# NUC400_v1 register map
File version: 1.0
Registers are 32-bit, read-write, reset 0x0 unless marked. A register's access mark holds for its fields unless they carry their own. Offsets are from the block's base; [hi:lo] are bit positions; 'fields as' and 'values as' point back to an identical list.

## UART0 — UART Register Map
Base 0x40070000
0x00 UART_DAT reset not defined — UARTx Receive / Transmit Buffer Register
  [7:0] DAT — Receiving/Transmit Buffer. Write Operation: By writing one byte to this register, the data byte will be stored in transmitter FIFO. The. UART Controller will send out the data stored in transmitter FIFO top location through the. UART_TXD. Read Operation: By reading this register, the UART will return an 8-bit data received from receiving FIFO
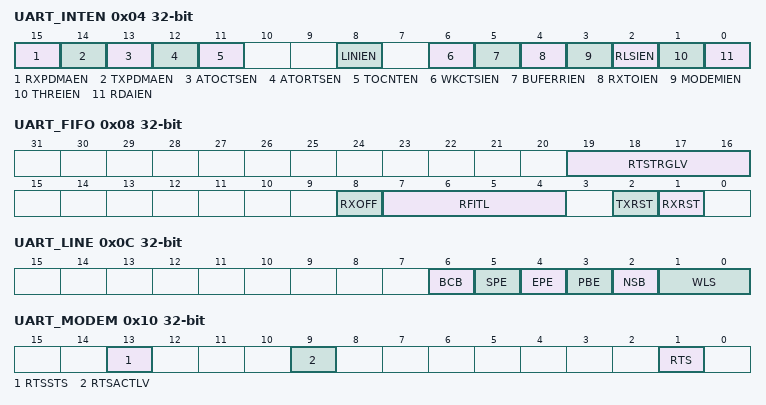
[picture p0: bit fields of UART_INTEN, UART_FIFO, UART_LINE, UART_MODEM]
0x04 UART_INTEN — UARTx Interrupt Enable Register
  [15] RXPDMAEN — RX DMA Enable Bit. This bit can enable or disable RX DMA service.
    0=RX DMA Disabled; 1=RX DMA Enabled
  [14] TXPDMAEN — TX DMA Enable Bit. This bit can enable or disable TX DMA service.
    0=TX DMA Disabled; 1=TX DMA Enabled
  [13] ATOCTSEN — CTS Auto Flow Control Enable Bit. When CTS auto-flow is enabled, the UART will send data to external device when CTS input assert (UART will not send data to device until CTS is asserted).
    0=CTS auto flow control Disabled; 1=CTS auto flow control Enabled
  [12] ATORTSEN — RTS Auto Flow Control Enable Bit. When RTS auto-flow is enabled, if the number of bytes in the RX FIFO equals the RTSTRGLV (UART_FIFO[19:16]), the UART will de-assert RTS signal.
    0=RTS auto flow control Disabled; 1=RTS auto flow control Enabled
  [11] TOCNTEN — Time-Out Counter Enable Bit
    0=Time-out counter Disabled; 1=Time-out counter Enabled
  [8] LINIEN — LIN RX Break Field Detected Interrupt Enable Bit. Note: This field is used for LIN function mode.
    0=Lin bus RX break filed interrupt Disabled; 1=Lin bus RX break filed interrupt Enabled
  [6] WKCTSIEN — UART Wake-Up Function Enable Bit
    0=UART wake-up function Disabled; 1=UART wake-up function Enabled when the chip is in Power-down mode, an external CTS change will wake up chip from Power-down mode
  [5] BUFERRIEN — Buffer Error Interrupt Enable Bit
    0=INT_BUF_ERR Disabled; 1=INT_BUF_ERR Enabled
  [4] RXTOIEN — RX Time-Out Interrupt Enable Bit
    0=NT_TOUT Disabled; 1=INT_TOUT Enabled
  [3] MODEMIEN — Modem Status Interrupt Enable Bit
    0=INT_MODEM Disabled; 1=INT_MODEM Enabled
  [2] RLSIEN — Receive Line Status Interrupt Enable Bit
    0=INT_RLS Disabled; 1=INT_RLS Enabled
  [1] THREIEN — Transmit Holding Register Empty Interrupt Enable Bit
    0=INT_THRE Disabled; 1=INT_THRE Enabled
  [0] RDAIEN — Receive Data Available Interrupt Enable Bit
    0=INT_RDA Disabled; 1=INT_RDA Enabled
0x08 UART_FIFO — UARTx FIFO Control Register
  [19:16] RTSTRGLV — RTS Trigger Level For Auto-Flow Control Use
  [8] RXOFF — Receiver Disable. The receiver is disabled or not. Note: This field is used for RS-485 Normal Multi-drop mode. It should be programmed before RS-485_NMM (UART_ALTCTL [8]) is programmed.
    0=Receiver Enabled; 1=Receiver Disabled
  [7:4] RFITL — RX FIFO Interrupt (INT_RDA) Trigger Level
  [2] TXRST — TX Field Software Reset. When TX_RST is set, all the byte in the transmit FIFO and TX internal state machine are cleared. Note: This bit will auto clear needs at least 3 UART engine clock cycles.
    0=No effect; 1=Reset the TX internal state machine and pointers
  [1] RXRST — RX Field Software Reset. When RX_RST is set, all the byte in the receiver FIFO and RX internal state machine are cleared. Note: This bit will be automatically cleared for at least 3 UART engine clock cycles.
    0=No effect; 1=Reset the RX internal state machine and pointers
0x0C UART_LINE — UARTx Line Control Register
  [6] BCB — Break Control. When this bit is set to logic 1, the serial data output (TX) is forced to the Spacing State (logic 0). This bit acts only on TX and has no effect on the transmitter logic.
  [5] SPE — Stick Parity Enable Bit
    0=Stick parity Disabled; 1=If bit 3 and 4 are logic 1, the parity bit is transmitted and checked as logic 0. If bit 3 is 1 and bit 4 is 0 then the parity bit is transmitted and checked as 1
  [4] EPE — Even Parity Enable Bit. This bit is effective only when bit 3 (parity bit enable) is set.
    0=Odd number of logic 1's is transmitted and checked in each word; 1=Even number of logic 1's is transmitted and checked in each word
  [3] PBE — Parity Bit Enable Bit
    0=No parity bit; 1=Parity bit is generated on each outgoing character and is checked on each incoming data
  [2] NSB — Number Of "STOP Bit" Two "STOP bit" is generated when 6-, 7- and 8-bit word length is selected.
    0=One " STOP bit" is generated in the transmitted data; 1=One and a half " STOP bit" is generated in the transmitted data when 5-bit word length is selected
  [1:0] WLS — Word Length Selection
0x10 UART_MODEM — UARTx Modem Control Register
  [13] RTSSTS ro — RTS Pin State (Read Only). This bit is the output pin status of RTS.
  [9] RTSACTLV — RTS Trigger Level. This bit can change the RTS trigger level.
    0=Low level triggered; 1=High level triggered
  [1] RTS — RTS (Request-To-Send) Signal
    0=Drive RTS pin to logic 1 (If the RTSACTLV set to low level triggered). Drive RTS pin to logic 0 (If the RTSACTLV set to high level triggered); 1=Drive RTS pin to logic 0 (If the RTSACTLV set to low level triggered). Drive RTS pin to logic 1 (If the RTSACTLV set to high level triggered)
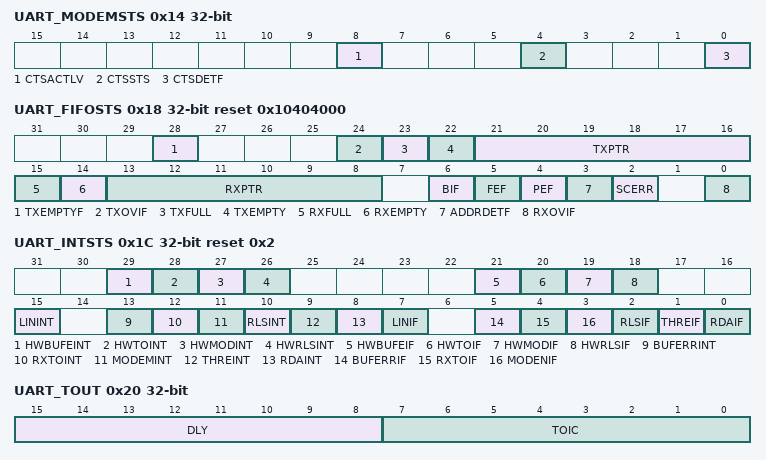
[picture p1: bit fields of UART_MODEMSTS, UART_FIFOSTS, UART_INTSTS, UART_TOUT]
0x14 UART_MODEMSTS — UARTx Modem Status Register
  [8] CTSACTLV — CTS Trigger Level. This bit can change the CTS trigger level.
    0=Low level triggered; 1=High level triggered
  [4] CTSSTS ro — CTS Pin Status (Read Only). This bit is the pin status of CTS.
  [0] CTSDETF ro — Detect CTS State Change Flag (Read Only). This bit is set whenever CTS input has change state, and it will generate Modem interrupt to CPU when MODEMIEN (UART_INTEN[3]) is set to 1. Software can write 1 to clear this bit to 0
0x18 UART_FIFOSTS reset 0x10404000 — UARTx FIFO Status Register
  [28] TXEMPTYF ro — Transmitter Empty Flag (Read Only). Bit is set by hardware when TX FIFO (UART_DAT) is empty and the STOP bit of the last byte has been transmitted. Bit is cleared automatically when TX FIFO is not empty or the last byte transmission has not completed.
  [24] TXOVIF ro — TX Overflow Error Interrupt Flag (Read Only). If TX FIFO (UART_DAT) is full, an additional write to UART_DAT will cause this bit to logic 1. Note: This bit is read only, but it can be cleared by writing '1' to it.
  [23] TXFULL ro — Transmitter FIFO Full (Read Only). This bit indicates TX FIFO full or not. This bit is set when TXPTR is equal to 64/16(UART0/UART1~5), otherwise is cleared by hardware.
  [22] TXEMPTY ro — Transmitter FIFO Empty (Read Only). This bit indicates TX FIFO empty or not. When the last byte of TX FIFO has been transferred to Transmitter Shift Register, hardware sets this bit high. It will be cleared when writing data into DAT (TX FIFO not empty).
  [21:16] TXPTR ro — TX FIFO Pointer (Read Only). This field indicates the TX FIFO Buffer Pointer. When CPU writes one byte into UART_DAT, TXPTR increases one. When one byte of TX FIFO is transferred to Transmitter Shift Register, TXPTR decreases one.
  [15] RXFULL ro — Receiver FIFO Full (Read Only). This bit initiates RX FIFO full or not. This bit is set when RXPTR is equal to 64/16(UART0/UART1~5), otherwise is cleared by hardware.
  [14] RXEMPTY ro — Receiver FIFO Empty (Read Only). This bit initiate RX FIFO empty or not. When the last byte of RX FIFO has been read by CPU, hardware sets this bit high. It will be cleared when UART receives any new data.
  [13:8] RXPTR ro — RX FIFO Pointer (Read Only). This field indicates the RX FIFO Buffer Pointer. When UART receives one byte from external device, RXPTR increases one. When one byte of RX FIFO is read by CPU, RXPTR decreases one.
  [6] BIF ro — Break Interrupt Flag (Read Only). This bit is set to a logic 1 whenever the received data input(RX) is held in the "spacing state" (logic 0) for longer than a full word transmission time (that is, the total time of "start bit" + data bits + parity + stop bits) and is reset whenever the CPU writes 1 to this bit. Note: This bit is read only, but it can be cleared by writing '1' to it.
  [5] FEF ro — Framing Error Flag (Read Only). This bit is set to logic 1 whenever the received character does not have a valid "stop bit" (that is, the stop bit following the last data bit or parity bit is detected as a logic 0), and is reset whenever the CPU writes 1 to this bit. Note: This bit is read only, but it can be cleared by writing '1' to it.
  [4] PEF ro — Parity Error Flag (Read Only). This bit is set to logic 1 whenever the received character does not have a valid "parity bit", and is reset whenever the CPU writes 1 to this bit. Note: This bit is read only, but it can be cleared by writing '1' to it.
  [3] ADDRDETF ro — RS-485 Address Byte Detection Flag (Read Only). Note1: This field is used for RS-485 function mode. Note2: This bit is read only, but it can be cleared by writing '1' to it.
  [2] SCERR — Smart Card Over Error Retry Flag. It is set to 1 when transmitter re-transmits over the retry number (TXRTY (UART_SCCTL[6:4])) or the receiver transfer error retry over retry number (RXRTY (UART_SCCTL[2:0])). Note1: This field is used for SC function mode. Note2: This bit is read only, but it can be cleared by writing '1' to it.
    0=No any transmitter re-transmits over or receiver transfer error retry over; 1=one of the transmitter re-transmits over active or receiver transfer error retry over active
  [0] RXOVIF ro — RX Overflow Error IF (Read Only). This bit is set when RX FIFO overflow. If the number of bytes of received data is greater than RX_FIFO (UART_DAT) size, 64/16 bytes of UART0/UART1, this bit will be set. Note: This bit is read only, but it can be cleared by writing '1' to it.
0x1C UART_INTSTS reset 0x2 — UARTx Interrupt Status Register
  [29] HWBUFEINT ro — In DMA Mode, Buffer Error Interrupt Indicator (Read Only). This bit is set if BUFERRIEN and HWBFERIF are both set to 1.
    0=No buffer error interrupt is generated in DMA mode; 1=The buffer error interrupt is generated in DMA mode
  [28] HWTOINT ro — In DMA Mode, Time-Out Interrupt Indicator (Read Only). This bit is set if RXTOIEN and HWTOIF are both set to 1.
    0=No Tout interrupt is generated in DMA mode; 1=Tout interrupt is generated in DMA mode
  [27] HWMODINT ro — In DMA Mode, MODEM Status Interrupt Indicator (Read Only). This bit is set if MODEMIEN and HWMODIF are both set to 1.
    0=No Modem interrupt is generated in DMA mode; 1=Modem interrupt is generated in DMA mode
  [26] HWRLSINT ro — In DMA Mode, Receive Line Status Interrupt Indicator (Read Only). This bit is set if RLSIEN and HWRLSIF are both set to 1.
    0=No RLS interrupt is generated in DMA mode; 1=RLS interrupt is generated in DMA mode
  [21] HWBUFEIF ro — In DMA Mode, Buffer Error Interrupt Flag (Read Only). This bit is set when the TX or RX FIFO overflows (TXOVIF or RXOVIF is set). When BERRIF is set, the transfer maybe is not correct. If BUFERRIEN bit (UART_INTEN [5]) is enabled, the buffer error interrupt will be generated. Note: This bit is cleared when both TXOVIF and RXOVIF are cleared.
  [20] HWTOIF ro — In DMA Mode, Time-Out Interrupt Flag (Read Only). This bit is set when the RX FIFO is not empty and no activities occurred in the RX FIFO and the time-out counter equal to TOIC. If TOCNTEN (UART_INTEN[11]) is enabled, the Time-out interrupt will be generated. Note: This bit is read only and user can read UART_DAT (RX is in active) to clear it.
  [19] HWMODIF ro — In DMA Mode, MODEM Interrupt Flag (Read Only). Note: This bit is read only and reset to 0 when bit CTSDETF is cleared by a write 1 on CTSDETF.
  [18] HWRLSIF ro — In DMA Mode, Receive Line Status Flag (Read Only). This bit is set when the RX receive data have parity error, framing error or break error (at least one of 3 bits, BIF, FEF and PEF, is set). If RLSIEN bit (UART_INTEN[2]) is enabled, the RLS interrupt will be generated. Note2: In SC function mode, this field includes "error retry over flag . Note3: This bit is read only and reset to 0 when all bits of BIF, FEF and PEF are cleared.
  [15] LININT ro — LIN Bus Interrupt Indicator (Read Only). This bit is set if LINIEN and LINIF are both set to 1.
    0=No LIN RX Break interrupt is generated; 1=LIN RX Break interrupt is generated
  [13] BUFERRINT ro — Buffer Error Interrupt Indicator (Read Only). This bit is set if BUFERRIEN and BERRIF are both set to 1.
    0=No buffer error interrupt is generated; 1=The buffer error interrupt is generated
  [12] RXTOINT ro — Time-Out Interrupt Indicator (Read Only). This bit is set if TOCNTEN and RXTOIF are both set to 1.
    0=No Tout interrupt is generated; 1=Tout interrupt is generated
  [11] MODEMINT ro — MODEM Status Interrupt Indicator (Read Only). This bit is set if MODEMIEN and MODENIF are both set to 1.
    0=No Modem interrupt is generated; 1=Modem interrupt is generated
  [10] RLSINT ro — Receive Line Status Interrupt Indicator (Read Only). This bit is set if RLSIEN and RLSIF are both set to 1.
    0=No RLS interrupt is generated; 1=RLS interrupt is generated
  [9] THREINT ro — Transmit Holding Register Empty Interrupt Indicator (Read Only). This bit is set if THREIEN and THREIF are both set to 1.
    0=No THRE interrupt is generated; 1=THRE interrupt is generated
  [8] RDAINT ro — Receive Data Available Interrupt Indicator (Read Only). This bit is set if RDAIEN and RDAIF are both set to 1.
    0=No RDA interrupt is generated; 1=RDA interrupt is generated
  [7] LINIF ro — LIN Bus Flag (Read Only). Note: This bit is cleared when both SLVHDETF and LIN_BRDER_F and BITEF and LINS_IDPENR_F and SLVHEF are cleared
  [5] BUFERRIF ro — Buffer Error Interrupt Flag (Read Only). This bit is set when the TX or RX FIFO overflows (TXOVIF or RXOVIF is set). When BERRIF is set, the transfer maybe is not correct. If BUFERRIEN bit (UART_INTEN[5]) is enabled, the buffer error interrupt will be generated. Note: This bit is cleared when both TXOVIF and RXOVIF are cleared.
  [4] RXTOIF ro — Time-Out Interrupt Flag (Read Only). This bit is set when the RX FIFO is not empty and no activities occurred in the RX FIFO and the time-out counter equal to TOIC. If TOCNTEN bit (UART_INTEN[11]) is enabled, the Time-out interrupt will be generated. Note: This bit is read only and user can read UART_DAT (RX is in active) to clear it.
  [3] MODENIF ro — MODEM Interrupt Flag (Read Only). Note: This bit is read only and reset to 0 when bit CTSDETF is cleared by a write 1 on CTSDETF.
  [2] RLSIF ro — Receive Line Interrupt Flag (Read Only). This bit is set when the RX receive data have parity error, framing error or break error (at least one of 3 bits, BIF, FEF and PEF, is set). If RLSIEN bit (UART_INTEN[2]) is enabled, the RLS interrupt will be generated. Note2: In SC function mode, this field includes "error retry over flag . Note3: This bit is read only and reset to 0 when all bits of BIF, FEF and PEF are cleared.
  [1] THREIF ro — Transmit Holding Register Empty Interrupt Flag (Read Only). This bit is set when the last data of TX FIFO is transferred to Transmitter Shift Register. If THREIEN bit (UART_INTEN[1]) is enabled, the THRE interrupt will be generated. Note: This bit is read only and it will be cleared when writing data into DAT (TX FIFO not empty).
  [0] RDAIF ro — Receive Data Available Interrupt Flag (Read Only). When the number of bytes in the RX FIFO equals the RFITL then the RDAIF will be set. If RDAIEN bit (UART_INTEN[0]) is enabled, the RDA interrupt will be generated. Note: This bit is read only and it will be cleared when the number of unread bytes of RX FIFO drops below the threshold level (RFITL).
0x20 UART_TOUT — UARTx Time-out Register
  [15:8] DLY — TX Delay Time Value. This field is use to programming the transfer delay time between the last stop bit and next start bit. . Note: The counter clock is baud rate clock
  [7:0] TOIC — Time-Out Interrupt Comparator
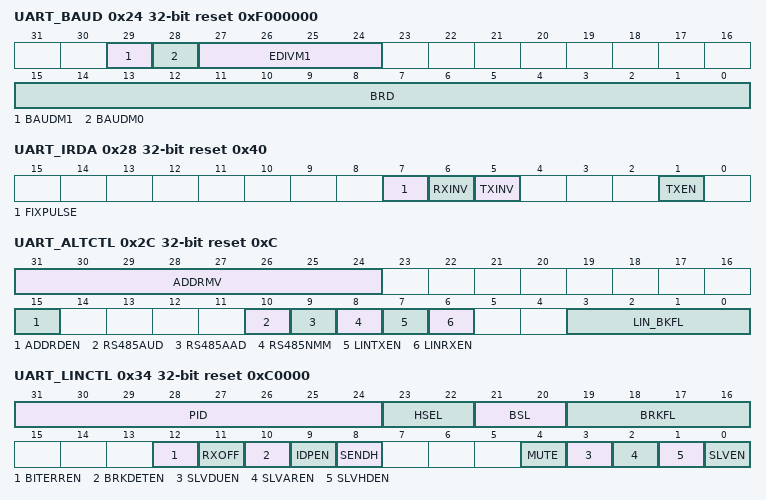
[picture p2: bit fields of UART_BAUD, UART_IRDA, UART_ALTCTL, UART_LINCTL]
0x24 UART_BAUD reset 0xF000000 — UARTx Baud Rate Divisor Register
  [29] BAUDM1 — Divider X Enable Bit. Refer to the table below for more information. Note: In IrDA mode, this bit must disable.
    0=Divider X Disabled (the equation of M = 16); 1=Divider X Enabled (the equation of M = X+1, but EDIVM1 (UART_BAUD[27:24]) must = 8)
  [28] BAUDM0 — Divider X Equal To 1. Refer to the table below for more information.
    0=Divider M = X (the equation of M = X+1, but EDIVM1 (UART_BAUD[27:24]) must = 8); 1=Divider M = 1 (the equation of M = 1, but BRD (UART_BAUD[15:0]) must = 3)
  [27:24] EDIVM1 — Divider X
  [15:0] BRD — Baud Rate Divider. The field indicated the baud rate divider
0x28 UART_IRDA reset 0x40 — UARTx IrDA Control Register
  [7] FIXPULSE — Pulse width of TX is fixed 1.6us.
  [6] RXINV — IrDA Inverse Receive Input Signal
    0=None inverse receiving input signal; 1=Inverse receiving input signal. (Default)
  [5] TXINV — IrDA Inverse Transmitting Output Signal
    0=None inverse transmitting signal. (Default); 1=Inverse transmitting output signal
  [1] TXEN — IrDA Receiver/Transmitter Selection Enable Bit
    0=IrDA Transmitter Disabled and Receiver Enabled. (Default); 1=IrDA Transmitter Enabled and Receiver Disabled
0x2C UART_ALTCTL reset 0xC — UARTx Alternate Control/Status Register
  [31:24] ADDRMV — Address Match Value. This field contains the RS-485 address match values. Note: This field is used for RS-485 auto address detection mode.
  [15] ADDRDEN — RS-485 Address Detection Enable Bit. This bit is use to enable RS-485 address detection mode. Note: This field is used for RS-485 any operation mode.
    0=address detection mode Disabled; 1=Address detection mode Enabled
  [10] RS485AUD — RS-485 Auto Direction Mode (AUD). Note: It can be active with RS-485_AAD or RS-485_NMM operation mode.
    0=RS-485 Auto Direction Operation (AUO) mode Disabled; 1=RS-485 Auto Direction Operation (AUO) mode Enabled
  [9] RS485AAD — RS-485 Auto Address Detection Operation Mode (AAD). Note: It can't be active with RS-485_NMM operation mode.
    0=RS-485 Auto Address Detection (AAD) Operation mode Disabled; 1=RS-485 Auto Address Detection (AAD) Operation mode Enabled
  [8] RS485NMM — RS-485 Normal Multi-Drop Operation Mode (NMM). Note: It can't be active with RS-485_AAD operation mode.
    0=RS-485 Normal Multi-drop Operation Mode (NMM) Disabled; 1=RS-485 Normal Multi-drop Operation Mode (NMM) Enabled
  [7] LINTXEN — LIN TX Break Mode Enable Bit. The LIN TX header can be "break field" or "break and sync field" or "break, sync and frame ID field" depending on the setting HSEL register. Note: When transmitter header field (it may be "break" or "break + sync" or "break + sync + frame ID" selected by HSEL field) transfer operation finished, this bit will be cleared automatically.
    0=Send LIN TX header Disabled; 1=Send LIN TX header Enabled
  [6] LINRXEN — LIN RX Enable Bit
    0=LIN RX mode Disabled; 1=LIN RX mode Enabled
  [3:0] LIN_BKFL — LIN Break Field Length. This field indicates a 4-bit LIN TX break field count. Note1: This break field length is BRKFL + 1.
0x30 UART_FUNCSEL — UARTx Function Select Register
  [2:0] FUNCSEL — Function Select Enable Bit
    0=UART function; 1=LIN function Enabled; 2=IrDA function Enabled; 3=RS-485 function Enabled; 4=Smart-Card function Enabled
0x34 UART_LINCTL reset 0xC0000 — UARTx LIN Control Register
  [31:24] PID — This Field Contains The LIN Frame ID Value In LIN Function Mode, The Frame ID Parity Can Be Generated By Software Or Hardware Depending On UART_LINCTL [IDPEN] . Note1: User can fill any 8-bit value to this field and the bit 24 indicates ID0 (LSB first). Note2: This field can be used for LIN Master mode or Slave mode.
  [23:22] HSEL — LIN Header Selection
    0=LIN header includes "break field"; 1=LIN header includes "break field" and "sync field"; 2=LIN header includes "break field", "sync field" and "frame ID field"; 3=LIN header includes "break field", "sync field" and "frame ID field", but this mode only supports Receiver mode, not support transmitter mode. This mode difference with mode "10"; in this mode, the receiver will receive ID field (not check the PID (UART_LINCTL[31:24]) register) and when received ID field the SLVHDETF will be asserted (if SLVHDEN (UART_LINCTL[1]) be set)
  [21:20] BSL — LIN Break/Sync Delimiter Length . Note: This bit used for LIN master to send header field.
    0=LIN break/sync delimiter length is 1 bit time; 2=The LIN break/sync delimiter length is 2 bit time. The LIN break/sync delimiter length is 3 bit time; 3=The LIN break/sync delimiter length is 4 bit time
  [19:16] BRKFL — LIN Break Field Length. This field indicates a 4-bit LIN TX break field count. Note1: These registers are shadow registers of LIN_BKFL (UART_ALTCTL[3:0]), User can read/write it by setting LIN_BKFL (UART_ALTCTL[3:0]) or LIN_BKFL (UART_LINCTL[19:16]). Note2: This break field length is BRKFL + 1.
  [12] BITERREN — Bit Error Detect Enable Bit. Note: In LIN function mode, when occur bit error, hardware will generate an interrupt to CPU (INT_LIN) and the BITEF (UART_LINSTS[9]) flag will be asserted.
    0=Bit error detection function Disabled; 1=Bit error detection Enabled
  [11] RXOFF
    values as BITERREN
  [10] BRKDETEN — LIN Break Detection Enable Bit
    0=LIN break detection Disabled; 1=LIN break detection Enabled
  [9] IDPEN — LIN ID Parity Enable Bit
    0=LIN frame ID parity Disabled; 1=LIN frame ID parity Enabled
  [8] SENDH — LIN TX Send Header Enable Bit. The LIN TX header can be "break field" or "break and sync field" or "break, sync and frame ID field" depending on the setting HSEL register. Note: When transmitter header field (it may be "break" or "break + sync" or "break + sync + frame ID" selected by HSEL field) transfer operation finished, this bit will be cleared automatically.
    0=Send LIN TX header Disabled; 1=Send LIN TX header Enabled
  [4] MUTE — LIN Mute Mode Enable Bit. Note: The wake-up condition from mute mode and each control and interactions of this field are explained in 6.16.5.3.
    0=LIN mute mode. Disabled; 1=LIN mute mode Enabled
  [3] SLVDUEN — LIN Slave Divider Update Method Enable Bit. Note2: This bit is used for LIN slave automatic resynchronization mode (for non-automatic resynchronization mode, this bit should be kept cleared). Note3: The control and interactions of this field are explained in 6.16.5.3.
    0=UART_BAUD is updated as soon as UART_BAUD is writing by software (if no automatic resynchronization update occurs at the same time); 1=UART_BAUD is updated at the next received character. User must set the bit before checksum reception
  [2] SLVAREN — LIN Slave Automatic Resynchronization Mode Enable Bit. Note2: When operating in Automatic Resynchronization mode, the baud rate setting must be mode2 (BAUDM1 (UART_BAUD[29]) and BAUDM0 (UART_BAUD[28]) must be 1). Note3: The control and interactions of this field are explained in 6.16.5.3.
    0=LIN automatic resynchronization Disabled; 1=LIN automatic resynchronization Enabled
  [1] SLVHDEN — LIN Slave Header Detection Enable Bit. Note2: In LIN function mode, when header field (break + sync + frame ID) is detected, hardware will generate an interrupt to CPU (INT_LIN) and the SLVHDETF flag (UART_LINSTS[0]) will be asserted.
    0=LIN slave header detection Disabled; 1=LIN slave header detection Enabled
  [0] SLVEN — LIN Slave Mode Enable Bit
    0=LIN slave mode Disabled; 1=LIN slave mode Enabled
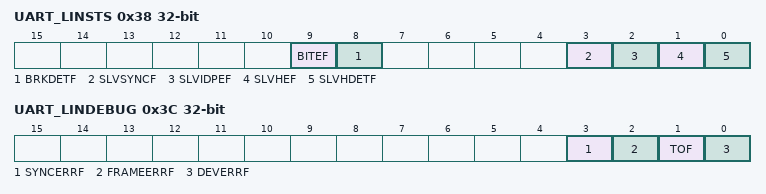
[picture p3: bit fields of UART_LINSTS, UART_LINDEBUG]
0x38 UART_LINSTS — UARTx LIN Status Register
  [9] BITEF ro — Bit Error Detect Status Flag (Read Only). At TX transfer state, hardware will monitoring the bus state, if the input pin (SIN) state not equals to the output pin (SOUT) state, BITEF will be set. When occur bit error, hardware will generate an interrupt to CPU (INT_LIN). Note1: This bit is read only, but can be cleared by writing 1 to it.
  [8] BRKDETF ro — LIN Break Detection Flag (Read Only). This bit is set by hardware when a break is detected and be cleared by writing 1 to it. Note1: This bit is read only, but can be cleared by writing 1 to it. Note2: This bit is only valid when enable LIN break detection function (BRKDETEN (UART_LINCTL[10]))
    0=LIN break not detected; 1=LIN break detected
  [3] SLVSYNCF — LIN Slave Sync Field. This bit indicates that the LIN sync field is being analyzed. When the receiver header have some error been detect, user must to reset the internal circuit to re-search new frame header by writing 1 to this bit. Note2: This bit is read only, but can be cleared by writing 1 to it. Note3: When user writing 1 to it, hardware will reload the initial baud-rate and re-search new frame header, the control and interactions of this field are explained in 6.16.5.3.
    0=The current character is not at LIN sync state; 1=The current character is at LIN sync state
  [2] SLVIDPEF ro — LIN Slave ID Parity Error Flag (Read Only). This bit is set by hardware when receipted frame ID parity is not correct.
    0=no active; 1=Receipted frame ID parity is not correct
  [1] SLVHEF ro — LIN Slave Header Error Flag (Read Only). This bit is set by hardware when a LIN header error is detected in LIN slave mode and be cleared by writing 1 to it. The header include "break delimiter is too short", "frame error in sync field or Identifier field", "sync field data is not 0x55 without automatic resynchronization mode", "sync field deviation error with automatic resynchronization mode", "sync field measure time-out with automatic resynchronization mode" and "LIN header reception time-out".
    0=LIN header error not detected; 1=LIN header error detected
  [0] SLVHDETF ro — LIN Slave Header Detection Flag (Read Only). This bit is set by hardware when a LIN header is detected in LIN slave mode and be cleared by writing 1 to it.
    0=LIN header not detected; 1=LIN header detected (break + sync + frame ID)
0x3C UART_LINDEBUG — UARTx LIN Debug Register
  [3] SYNCERRF ro — LIN Header Sync Data Error (Read Only). This bit indicates the header error cause by the LIN received sync data is not 0x55.
  [2] FRAMEERRF ro — LIN Header Frame Error Flag (Read Only). This bit indicates the header error cause by break delimiter is too short or frame error in sync field or Identifier field.
  [1] TOF ro — LIN Header Time-Out (Read Only). This bit indicates the header error cause by the LIN header reception time-out.
  [0] DEVERRF ro — LIN Header Deviation Error (Read Only). This bit indicates the header error cause by the sync field deviation error or sync field measure time-out with automatic resynchronization mode.
0x40 UART_SCCTL — UARTx SC Control Register
0x44 UART_SCSTATUS — UARTx SC Flag Status Register

## UART1 — UART Register Map
Base 0x40071000
Registers as UART0; these are added or differ:
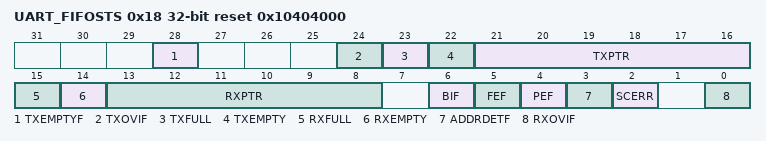
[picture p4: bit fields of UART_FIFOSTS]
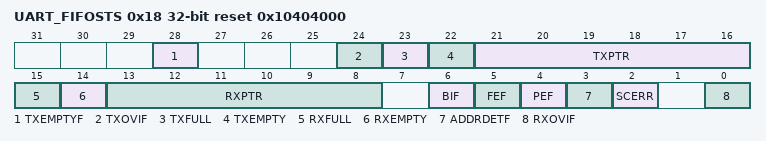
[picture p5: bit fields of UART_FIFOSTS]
0x18 UART_FIFOSTS reset 0x10404000 — UARTx FIFO Status Register
  fields as UART0.UART_FIFOSTS

## UART2 — UART Register Map
Base 0x40072000
Same registers: UART3 0x40073000, UART4 0x40074000, UART5 0x40075000
Registers as UART0; these are added or differ:
0x18 UART_FIFOSTS reset 0x10404000 — UARTx FIFO Status Register
  fields as UART0.UART_FIFOSTS
